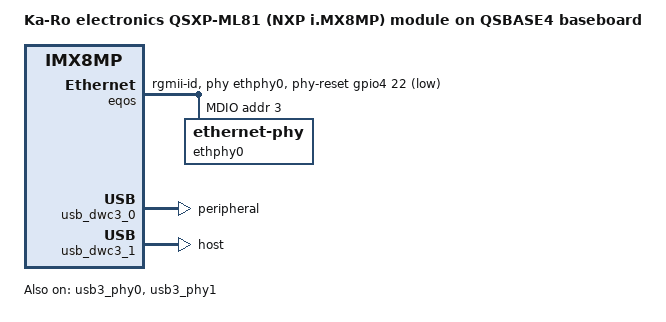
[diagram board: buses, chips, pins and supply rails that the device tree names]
// SPDX-License-Identifier: (GPL-2.0 OR MIT)
/*
 * Copyright (C) 2020 Lothar Waßmann <LW@KARO-electronics.de>
 *
 */

/dts-v1/;

#include "imx8mp-qsxp-ml81.dts"

/ {
	model = "Ka-Ro electronics QSXP-ML81 (NXP i.MX8MP) module on QSBASE4 baseboard";
};

&eqos {
	pinctrl-names = "default";
	pinctrl-0 = <&pinctrl_eqos &pinctrl_etnphy_rst_b>;
	phy-mode = "rgmii-id";
	phy-handle = <&ethphy0>;
	phy-reset-gpios = <&gpio4 22 GPIO_ACTIVE_LOW>;
	phy-reset-duration-us =   <10000>;
	phy-reset-post-delay-us = <10000>;
	status = "okay";

	mdio {
		#address-cells = <1>;
		#size-cells = <0>;

		ethphy0: ethernet-phy@3 {
			reg = <3>;
		};
	};
};

&usb_dwc3_0 {
	dr_mode = "peripheral";
	hnp-disable;
	srp-disable;
	adp-disable;
	status = "okay";
};

&usb_dwc3_1 {
	dr_mode = "host";
	status = "okay";
};

&usb3_phy0 {
	status = "okay";
};

&usb3_phy1 {
	status = "okay";
};

&usdhc2 {
	status = "disabled";
};

&iomuxc {
	pinctrl_etnphy_rst_b: etnphy-rst-bgrp {
		fsl,pins = <
			    MX8MP_IOMUXC_SAI2_RXC__GPIO4_IO22			0x140
		>;
	};

	pinctrl_eqos: eqosgrp {
		fsl,pins = <
			    MX8MP_IOMUXC_ENET_MDC__ENET_QOS_MDC			0x142
			    MX8MP_IOMUXC_ENET_MDIO__ENET_QOS_MDIO		0x142
			    MX8MP_IOMUXC_ENET_TXC__CCM_ENET_QOS_CLOCK_GENERATE_TX_CLK 0x40000016
			    MX8MP_IOMUXC_ENET_TD0__ENET_QOS_RGMII_TD0		0x016
			    MX8MP_IOMUXC_ENET_TD1__ENET_QOS_RGMII_TD1		0x016
			    MX8MP_IOMUXC_ENET_TD2__ENET_QOS_RGMII_TD2		0x016
			    MX8MP_IOMUXC_ENET_TD3__ENET_QOS_RGMII_TD3		0x016
			    MX8MP_IOMUXC_ENET_TX_CTL__ENET_QOS_RGMII_TX_CTL	0x016
			    MX8MP_IOMUXC_ENET_RD0__ENET_QOS_RGMII_RD0		0x150
			    MX8MP_IOMUXC_ENET_RD1__ENET_QOS_RGMII_RD1		0x150
			    MX8MP_IOMUXC_ENET_RD2__ENET_QOS_RGMII_RD2		0x150
			    MX8MP_IOMUXC_ENET_RD3__ENET_QOS_RGMII_RD3		0x150
			    MX8MP_IOMUXC_ENET_RXC__CCM_ENET_QOS_CLOCK_GENERATE_RX_CLK 0x116
			    /* CLK125_NDO: disable: 0x116, enable: 0x156 */
			    MX8MP_IOMUXC_ENET_RX_CTL__ENET_QOS_RGMII_RX_CTL	0x156
			    /* LED_MODE: dual-led/tri-color: 0x110 single LED: 0x150 */
			    MX8MP_IOMUXC_GPIO1_IO00__GPIO1_IO00			0x110
		>;
	};
};
